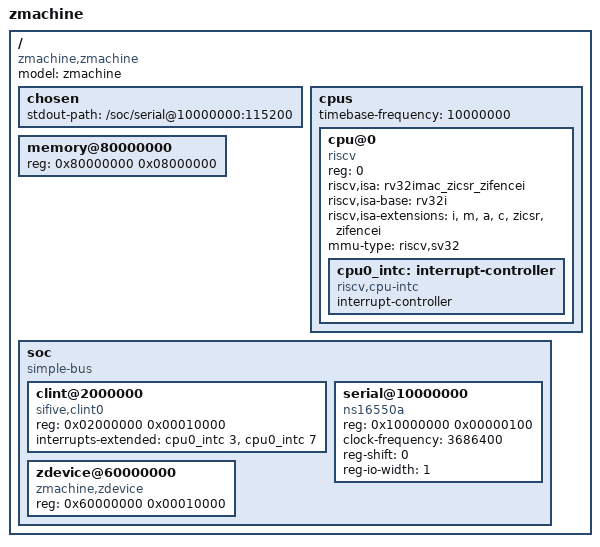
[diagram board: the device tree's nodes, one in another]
/dts-v1/;

/*
 * Device tree for the "zmachine" platform: a bare-minimum RISC-V machine
 * (one hart, RAM, CLINT, one 8250 UART) plus the custom zdevice peripheral.
 *
 * Keep this file in sync with the constants in platform.c and with the QEMU
 * machine model.
 */

/ {
	#address-cells = <1>;
	#size-cells = <1>;
	compatible = "zmachine,zmachine";
	model = "zmachine";

	chosen {
		stdout-path = "/soc/serial@10000000:115200";
	};

	cpus {
		#address-cells = <1>;
		#size-cells = <0>;
		timebase-frequency = <10000000>;

		cpu@0 {
			device_type = "cpu";
			reg = <0>;
			status = "okay";
			compatible = "riscv";
			riscv,isa = "rv32imac_zicsr_zifencei";
			riscv,isa-base = "rv32i";
			riscv,isa-extensions = "i", "m", "a", "c",
					       "zicsr", "zifencei";
			mmu-type = "riscv,sv32";

			cpu0_intc: interrupt-controller {
				#interrupt-cells = <1>;
				interrupt-controller;
				compatible = "riscv,cpu-intc";
			};
		};
	};

	memory@80000000 {
		device_type = "memory";
		/* 128 MiB */
		reg = <0x80000000 0x08000000>;
	};

	soc {
		#address-cells = <1>;
		#size-cells = <1>;
		compatible = "simple-bus";
		ranges;

		clint@2000000 {
			compatible = "sifive,clint0", "riscv,clint0";
			reg = <0x02000000 0x00010000>;
			interrupts-extended = <&cpu0_intc 3>, <&cpu0_intc 7>;
		};

		serial@10000000 {
			compatible = "ns16550a";
			reg = <0x10000000 0x00000100>;
			clock-frequency = <3686400>;
			reg-shift = <0>;
			reg-io-width = <1>;
		};

		/*
		 * zdevice: 64 KB MMIO window.
		 *
		 *   +0x0040  xor key		(16-bit)
		 *   +0x0042  left shift toggle	(16-bit)
		 *   +0x0100  data scratchpad	(to the end of the window)
		 *
		 * A halfword written to the scratchpad is stored as
		 *   (value ^ key) << (toggle ? 2 : 0)
		 */
		zdevice@60000000 {
			compatible = "zmachine,zdevice";
			reg = <0x60000000 0x00010000>;
			status = "okay";
		};
	};
};
